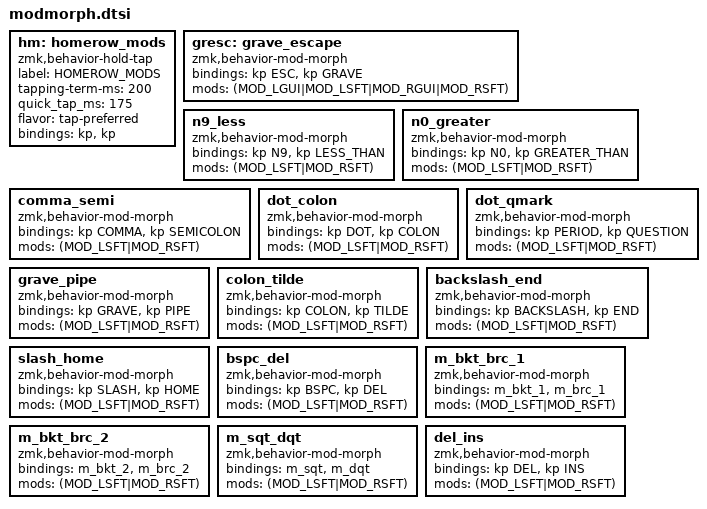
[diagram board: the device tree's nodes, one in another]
hm: homerow_mods {
  compatible = "zmk,behavior-hold-tap";
  label = "HOMEROW_MODS";
  #binding-cells = <2>;
  tapping-term-ms = <200>;
  quick_tap_ms = <175>;
  flavor = "tap-preferred";
  bindings = <&kp>, <&kp>;
};

gresc: grave_escape {
  compatible = "zmk,behavior-mod-morph";
  #binding-cells = <0>;
  bindings = <&kp ESC>, <&kp GRAVE>;
  mods = <(MOD_LGUI|MOD_LSFT|MOD_RGUI|MOD_RSFT)>;
};

n9_less: n9_less {
  compatible = "zmk,behavior-mod-morph";
  #binding-cells = <0>;
  bindings = <&kp N9>, <&kp LESS_THAN>;
  mods = <(MOD_LSFT|MOD_RSFT)>;
};

n0_greater: n0_greater {
  compatible = "zmk,behavior-mod-morph";
  #binding-cells = <0>;
  bindings = <&kp N0>, <&kp GREATER_THAN>;
  mods = <(MOD_LSFT|MOD_RSFT)>;
};

comma_semi: comma_semi {
  compatible = "zmk,behavior-mod-morph";
  #binding-cells = <0>;
  bindings = <&kp COMMA>, <&kp SEMICOLON>;
  mods = <(MOD_LSFT|MOD_RSFT)>;
};

dot_colon: dot_colon {
  compatible = "zmk,behavior-mod-morph";
  #binding-cells = <0>;
  bindings = <&kp DOT>, <&kp COLON>;
  mods = <(MOD_LSFT|MOD_RSFT)>;
};

dot_qmark: dot_qmark {
  compatible = "zmk,behavior-mod-morph";
  #binding-cells = <0>;
  bindings = <&kp PERIOD>, <&kp QUESTION>;
  mods = <(MOD_LSFT|MOD_RSFT)>;
};

grave_pipe: grave_pipe {
  compatible = "zmk,behavior-mod-morph";
  #binding-cells = <0>;
  bindings = <&kp GRAVE>, <&kp PIPE>;
  mods = <(MOD_LSFT|MOD_RSFT)>;
};

colon_tilde: colon_tilde {
  compatible = "zmk,behavior-mod-morph";
  #binding-cells = <0>;
  bindings = <&kp COLON>, <&kp TILDE>;
  mods = <(MOD_LSFT|MOD_RSFT)>;
};

backslash_end: backslash_end {
  compatible = "zmk,behavior-mod-morph";
  #binding-cells = <0>;
  bindings = <&kp BACKSLASH>, <&kp END>;
  mods = <(MOD_LSFT|MOD_RSFT)>;
};

slash_home: slash_home {
  compatible = "zmk,behavior-mod-morph";
  #binding-cells = <0>;
  bindings = <&kp SLASH>, <&kp HOME>;
  mods = <(MOD_LSFT|MOD_RSFT)>;
};

bspc_del: bspc_del  {
  compatible = "zmk,behavior-mod-morph";
  #binding-cells = <0>;
  bindings = <&kp BSPC>, <&kp DEL>;
  mods = <(MOD_LSFT|MOD_RSFT)>;
};

m_bkt_brc_1: m_bkt_brc_1 {
  compatible = "zmk,behavior-mod-morph";
  #binding-cells = <0>;
  bindings = <&m_bkt_1>, <&m_brc_1>;
  mods = <(MOD_LSFT|MOD_RSFT)>;
};

m_bkt_brc_2: m_bkt_brc_2 {
  compatible = "zmk,behavior-mod-morph";
  #binding-cells = <0>;
  bindings = <&m_bkt_2>, <&m_brc_2>;
  mods = <(MOD_LSFT|MOD_RSFT)>;
};

m_sqt_dqt: m_sqt_dqt {
  compatible = "zmk,behavior-mod-morph";
  #binding-cells = <0>;
  bindings = <&m_sqt>, <&m_dqt>;
  mods = <(MOD_LSFT|MOD_RSFT)>;
};

del_ins: del_ins {
  compatible = "zmk,behavior-mod-morph";
  #binding-cells = <0>;
  bindings = <&kp DEL>, <&kp INS>;
  mods = <(MOD_LSFT|MOD_RSFT)>;
};
